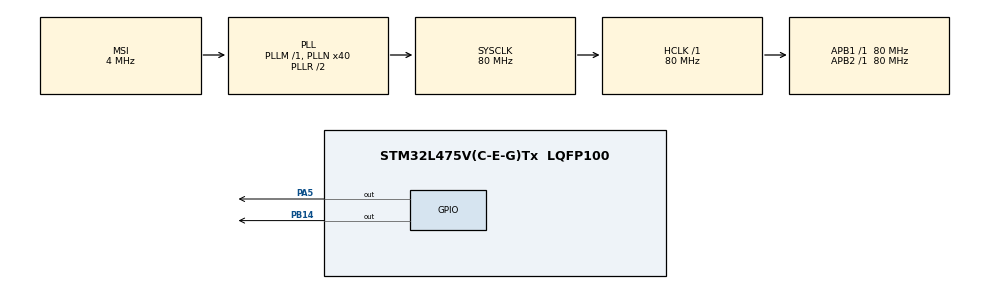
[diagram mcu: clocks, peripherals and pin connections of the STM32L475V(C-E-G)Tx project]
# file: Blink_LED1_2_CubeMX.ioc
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Mcu.Family=STM32L4
Mcu.Name=STM32L475V(C-E-G)Tx
Mcu.Package=LQFP100
NVIC.PriorityGroup=NVIC_PRIORITYGROUP_4
PA5.Signal=GPIO_Output
PB14.Signal=GPIO_Output
ProjectManager.HeapSize=0x200
ProjectManager.StackSize=0x400
ProjectManager.TargetToolchain=EWARM V8.32
RCC.ADCFreq_Value=48000000
RCC.AHBFreq_Value=80000000
RCC.APB1Freq_Value=80000000
RCC.APB1TimFreq_Value=80000000
RCC.APB2Freq_Value=80000000
RCC.APB2TimFreq_Value=80000000
RCC.CortexFreq_Value=80000000
RCC.HCLKFreq_Value=80000000
RCC.HSE_VALUE=8000000
RCC.HSI_VALUE=16000000
RCC.MSI_VALUE=4000000
RCC.PLLN=40
RCC.PLLSAI1N=24
RCC.SYSCLKFreq_VALUE=80000000
RCC.SYSCLKSource=RCC_SYSCLKSOURCE_PLLCLK
RCC.USBFreq_Value=48000000
RCC.VCOOutputFreq_Value=160000000
board=B-L475E-IOT01A1

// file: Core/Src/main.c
/* USER CODE BEGIN Header */
/**
  ******************************************************************************
  * @file           : main.c
  * @brief          : Main program body
  ******************************************************************************
  * @attention
  *
  * <h2><center>&copy; Copyright (c) 2020 STMicroelectronics.
  * All rights reserved.</center></h2>
  *
  * This software component is licensed by ST under BSD 3-Clause license,
  * the "License"; You may not use this file except in compliance with the
  * License. You may obtain a copy of the License at:
  *                        opensource.org/licenses/BSD-3-Clause
  *
  ******************************************************************************
  */
/* USER CODE END Header */
#include "main.h"

void SystemClock_Config(void);
static void MX_GPIO_Init(void);

int main(void)
{

  /* MCU Configuration--------------------------------------------------------*/

  /* Reset of all peripherals, Initializes the Flash interface and the Systick. */
  HAL_Init();

  /* Configure the system clock */
  SystemClock_Config();

  /* Initialize all configured peripherals */
  MX_GPIO_Init();

  /* Infinite loop */
  /* USER CODE BEGIN WHILE */
  while (1)
  {

    HAL_GPIO_WritePin(GPIOA, GPIO_PIN_5, GPIO_PIN_SET);
    HAL_GPIO_WritePin(GPIOB, GPIO_PIN_14, GPIO_PIN_RESET);

    // 1 tick equals 1 millisecond
    // delay 1s
    HAL_Delay(1000);

    HAL_GPIO_WritePin(GPIOA, GPIO_PIN_5, GPIO_PIN_RESET);
    HAL_GPIO_WritePin(GPIOB, GPIO_PIN_14, GPIO_PIN_SET);

     // 1 tick equals 1 millisecond
    // delay 1s
    HAL_Delay(1000);

    /* USER CODE END WHILE */

  }
}

void SystemClock_Config(void)
{
  RCC_OscInitTypeDef RCC_OscInitStruct = {0};
  RCC_ClkInitTypeDef RCC_ClkInitStruct = {0};

  /** Initializes the RCC Oscillators according to the specified parameters
  * in the RCC_OscInitTypeDef structure.
  */
  RCC_OscInitStruct.OscillatorType = RCC_OSCILLATORTYPE_MSI;
  RCC_OscInitStruct.MSIState = RCC_MSI_ON;
  RCC_OscInitStruct.MSICalibrationValue = 0;
  RCC_OscInitStruct.MSIClockRange = RCC_MSIRANGE_6;
  RCC_OscInitStruct.PLL.PLLState = RCC_PLL_ON;
  RCC_OscInitStruct.PLL.PLLSource = RCC_PLLSOURCE_MSI;
  RCC_OscInitStruct.PLL.PLLM = 1;
  RCC_OscInitStruct.PLL.PLLN = 40;
  RCC_OscInitStruct.PLL.PLLP = RCC_PLLP_DIV7;
  RCC_OscInitStruct.PLL.PLLQ = RCC_PLLQ_DIV2;
  RCC_OscInitStruct.PLL.PLLR = RCC_PLLR_DIV2;
  if (HAL_RCC_OscConfig(&RCC_OscInitStruct) != HAL_OK)
  {
    Error_Handler();
  }
  /** Initializes the CPU, AHB and APB buses clocks
  */
  RCC_ClkInitStruct.ClockType = RCC_CLOCKTYPE_HCLK|RCC_CLOCKTYPE_SYSCLK
                              |RCC_CLOCKTYPE_PCLK1|RCC_CLOCKTYPE_PCLK2;
  RCC_ClkInitStruct.SYSCLKSource = RCC_SYSCLKSOURCE_PLLCLK;
  RCC_ClkInitStruct.AHBCLKDivider = RCC_SYSCLK_DIV1;
  RCC_ClkInitStruct.APB1CLKDivider = RCC_HCLK_DIV1;
  RCC_ClkInitStruct.APB2CLKDivider = RCC_HCLK_DIV1;

  if (HAL_RCC_ClockConfig(&RCC_ClkInitStruct, FLASH_LATENCY_4) != HAL_OK)
  {
    Error_Handler();
  }
  /** Configure the main internal regulator output voltage
  */
  if (HAL_PWREx_ControlVoltageScaling(PWR_REGULATOR_VOLTAGE_SCALE1) != HAL_OK)
  {
    Error_Handler();
  }
}

static void MX_GPIO_Init(void)
{
  GPIO_InitTypeDef GPIO_InitStruct = {0};

  /* GPIO Ports Clock Enable */
  __HAL_RCC_GPIOA_CLK_ENABLE();
  __HAL_RCC_GPIOB_CLK_ENABLE();

  /*Configure GPIO pin Output Level */
  HAL_GPIO_WritePin(GPIOA, GPIO_PIN_5, GPIO_PIN_RESET);

  /*Configure GPIO pin Output Level */
  HAL_GPIO_WritePin(GPIOB, GPIO_PIN_14, GPIO_PIN_RESET);

  /*Configure GPIO pin : PA5 */
  GPIO_InitStruct.Pin = GPIO_PIN_5;
  GPIO_InitStruct.Mode = GPIO_MODE_OUTPUT_PP;
  GPIO_InitStruct.Pull = GPIO_NOPULL;
  GPIO_InitStruct.Speed = GPIO_SPEED_FREQ_LOW;
  HAL_GPIO_Init(GPIOA, &GPIO_InitStruct);

  /*Configure GPIO pin : PB14 */
  GPIO_InitStruct.Pin = GPIO_PIN_14;
  GPIO_InitStruct.Mode = GPIO_MODE_OUTPUT_PP;
  GPIO_InitStruct.Pull = GPIO_NOPULL;
  GPIO_InitStruct.Speed = GPIO_SPEED_FREQ_LOW;
  HAL_GPIO_Init(GPIOB, &GPIO_InitStruct);

}

void Error_Handler(void)
{
}

/************************ (C) COPYRIGHT STMicroelectronics *****END OF FILE****/
